# EFR32MG21B020F768IM32 register map
Vendor: Silicon Labs; Series: EFR32; File version: D
Registers are 32-bit, read-write, reset 0x0 unless marked. A register's access mark holds for its fields unless they carry their own. Offsets are from the block's base; [hi:lo] are bit positions; {n}, {i} and the like mark numbered series.

## MSC_NS — MSC_NS Registers
Base 0x50030000
Same registers: MSC_S 0x40030000
0x00 IPVERSION ro reset 0x6
  [31:0] IPVERSION — IP Version ID
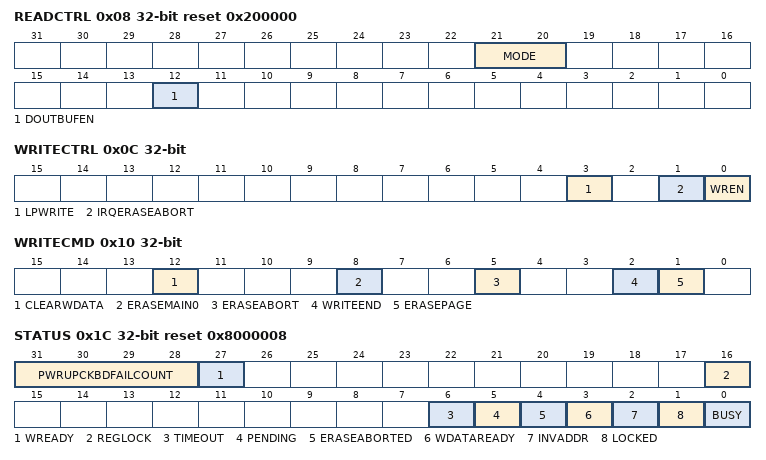
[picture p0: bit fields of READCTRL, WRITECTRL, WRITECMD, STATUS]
0x08 READCTRL reset 0x200000
  [21:20] MODE — Read Mode
    0=WS0 (Zero wait-states inserted in fetch or read transfers); 1=WS1 (One wait-state inserted for each fetch or read transfer. See Flash Wait-States table for details); 2=WS2 (Two wait-states inserted for eatch fetch or read transfer. See Flash Wait-States table for details); 3=WS3 (Three wait-states inserted for eatch fetch or read transfer. See Flash Wait-States table for details)
  [12] DOUTBUFEN — Flash dout pipeline buffer enable
0x0C WRITECTRL
  [3] LPWRITE — Low-Power Write
  [1] IRQERASEABORT — Abort Page Erase on Interrupt
  [0] WREN — Enable Write/Erase Controller
0x10 WRITECMD wo
  [12] CLEARWDATA — Clear WDATA state
  [8] ERASEMAIN0 — Mass erase region 0
  [5] ERASEABORT — Abort erase sequence
  [2] WRITEEND — End Write Mode
  [1] ERASEPAGE
0x14 ADDRB
  [31:0] ADDRB — Page Erase or Write Address Buffer
0x18 WDATA
  [31:0] DATAW — Write Data
0x1C STATUS ro reset 0x8000008
  [31:28] PWRUPCKBDFAILCOUNT — Flash power up checkerboard pattern chec
  [27] WREADY — Flash Write Ready
  [16] REGLOCK — Register Lock Status
    0=UNLOCKED; 1=LOCKED
  [6] TIMEOUT — Write Command Timeout
  [5] PENDING — Write Command In Queue
  [4] ERASEABORTED — Erase Operation Aborted
  [3] WDATAREADY — WDATA Write Ready
  [2] INVADDR — Invalid Write Address or Erase Page
  [1] LOCKED — Access Locked
  [0] BUSY — Erase/Write Busy
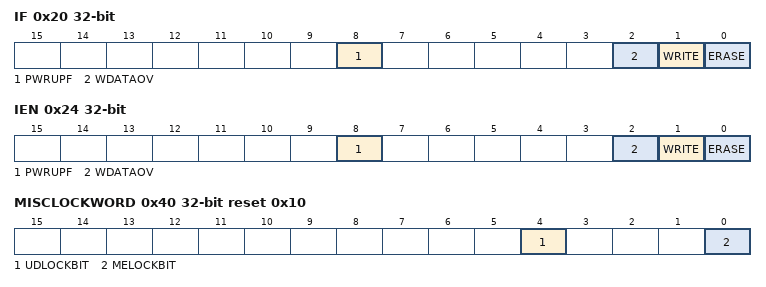
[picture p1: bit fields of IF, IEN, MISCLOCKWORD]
0x20 IF
  [8] PWRUPF — Flash Power Up Sequence Complete Flag
  [2] WDATAOV — Host write buffer overflow
  [1] WRITE — Host Write Done Interrupt Read Flag
  [0] ERASE — Host Erase Done Interrupt Read Flag
0x24 IEN
  [8] PWRUPF — Flash Power Up Sequence Complete
  [2] WDATAOV — write data buffer overflow irq enable
  [1] WRITE — Write Done Interrupt enable
  [0] ERASE — Erase Done Interrupt enable
0x34 USERDATASIZE ro reset 0x4
  [5:0] USERDATASIZE
0x38 CMD wo
  [0] PWRUP — Flash Power Up Command
0x3C LOCK wo
  [15:0] LOCKKEY — Configuration Lock
    0=LOCK; 0x1B71=UNLOCK
0x40 MISCLOCKWORD reset 0x10
  [4] UDLOCKBIT — User Data Lock
  [0] MELOCKBIT — Mass Erase Lock
{0x120+4i} PAGELOCK{i} (i=0..3)
  [31:0] LOCKBIT — page lock bit

## RADIOAES_NS — RADIOAES_NS Registers
Base 0x54000000
Same registers: RADIOAES_S 0x44000000
0x00 FETCHADDR — Fetcher: Start address of data block
  [31:0] ADDR — Start address of data block
0x04 FETCHDESCR — Fetcher: Descriptor address (Should be renamed to match Barco doc after PG)
  [31:0] DESCR — Descriptor address
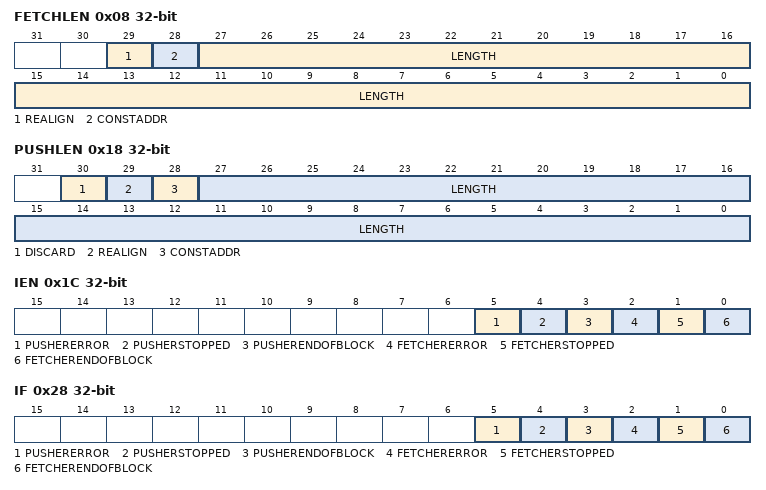
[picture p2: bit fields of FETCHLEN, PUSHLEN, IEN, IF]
0x08 FETCHLEN — Fetcher: Length of data block
  [29] REALIGN — Realign lengh
  [28] CONSTADDR — Constant address
  [27:0] LENGTH — Length of data block
0x0C FETCHTAG — Fetcher: User tag
  [31:0] TAG — User tag
0x10 PUSHADDR — Pusher: Start address of data block
  [31:0] ADDR — Start address of data block
0x14 PUSHDESCR — Pusher: Descriptor address (Should be renamed to match Barco doc after PG)
  [31:0] DESCR — Descriptor address
0x18 PUSHLEN — Pusher: Length of data block
  [30] DISCARD — Discard data
  [29] REALIGN — Realign length
  [28] CONSTADDR — Constant address
  [27:0] LENGTH — Start address of data block
0x1C IEN — Interrupt enable
  [5] PUSHERERROR — Error interrupt enable
  [4] PUSHERSTOPPED — Stopped interrupt enable
  [3] PUSHERENDOFBLOCK — End of block interrupt enable
  [2] FETCHERERROR — Error interrupt enable
  [1] FETCHERSTOPPED — Stopped interrupt enable
  [0] FETCHERENDOFBLOCK — End of block interrupt enable
0x28 IF ro — Interrupt flag register
  [5] PUSHERERROR — Error interrupt flag
  [4] PUSHERSTOPPED — Stopped interrupt flag
  [3] PUSHERENDOFBLOCK — End of block interrupt flag
  [2] FETCHERERROR — Error interrupt flag
  [1] FETCHERSTOPPED — Stopped interrupt flag
  [0] FETCHERENDOFBLOCK — End of block interrupt flag
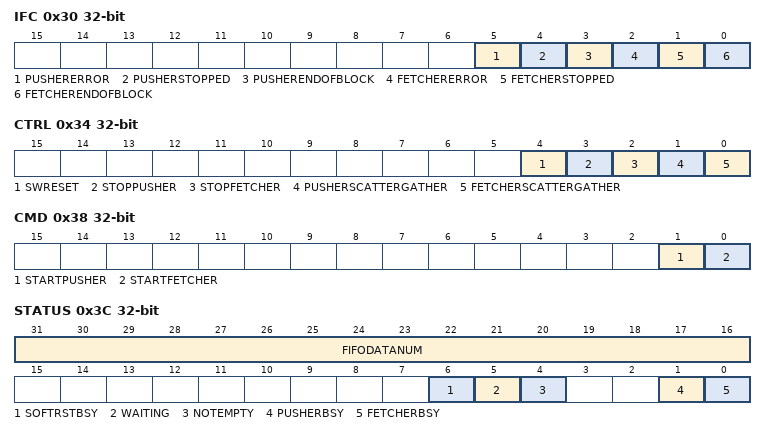
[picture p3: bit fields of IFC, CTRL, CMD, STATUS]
0x30 IFC wo — Writing a '1' clears the interrupt status. Writing a '0' has no effect.
  [5] PUSHERERROR — New BitField
  [4] PUSHERSTOPPED — New BitField
  [3] PUSHERENDOFBLOCK — New BitField
  [2] FETCHERERROR — Error interrupt flag clear
  [1] FETCHERSTOPPED — Stopped interrupt flag clear
  [0] FETCHERENDOFBLOCK — End of block interrupt flag clear
0x34 CTRL — Control register, called CONFIG in Barco datasheet.
  [4] SWRESET — Software reset
  [3] STOPPUSHER
  [2] STOPFETCHER
  [1] PUSHERSCATTERGATHER
  [0] FETCHERSCATTERGATHER
0x38 CMD wo — Command register for starting the fetcher and pusher
  [1] STARTPUSHER — Start push
  [0] STARTFETCHER — Start fetch
0x3C STATUS ro
  [31:16] FIFODATANUM — Number of data in output FIFO
  [6] SOFTRSTBSY — Software reset busy
  [5] WAITING — Pusher waiting for FIFO
  [4] NOTEMPTY — Not empty flag from input FIFO (fetcher)
  [1] PUSHERBSY — Pusher busy
  [0] FETCHERBSY — Fetcher busy
